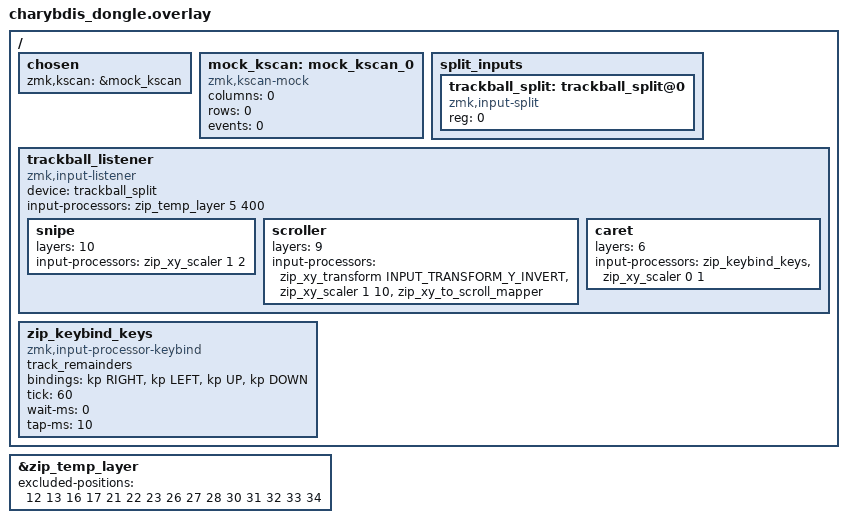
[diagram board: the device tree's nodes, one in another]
#include "../charybdis/charybdis-layout.dtsi"
#include <input/processors.dtsi>
#include <behaviors.dtsi>
#include <dt-bindings/zmk/keys.h>

/ {
    chosen {
        zmk,kscan = &mock_kscan;
    };

    mock_kscan: mock_kscan_0 {
        compatible = "zmk,kscan-mock";
        columns = <0>;
        rows = <0>;
        events = <0>;
    };

    split_inputs {
        #address-cells = <1>;
        #size-cells = <0>;
        trackball_split: trackball_split@0 {
            compatible = "zmk,input-split";
            reg = <0>;
        };
    };

    trackball_listener: trackball_listener {
        compatible = "zmk,input-listener";
        device = <&trackball_split>;
    };

    zip_keybind_keys: zip_keybind_keys {
        compatible = "zmk,input-processor-keybind";
        #input-processor-cells = <0>;
        track_remainders;
        bindings = <&kp RIGHT>,
                   <&kp LEFT>,
                   <&kp UP>,
                   <&kp DOWN>;
        tick = <60>;
        wait-ms = <0>;
        tap-ms = <10>;
    };
};

&zip_temp_layer {
    excluded-positions = <12 13 16 17 21 22 23 26 27 28 30 31 32 33 34>;
};

&trackball_listener {
    // automouse: при движении шара включается слой 5, выключается через 400 мс покоя
    input-processors = <&zip_temp_layer 5 400>;

    snipe {
        layers = <10>;
    // чем больше делитель (2), тем медленнее движется шар
        input-processors = <&zip_xy_scaler 1 2>;
    };

    scroller {
        layers = <9>;
        // чем больше делитель (10), тем медленнее работает скролл
        input-processors = <&zip_xy_transform INPUT_TRANSFORM_Y_INVERT
                            &zip_xy_scaler 1 10
                            &zip_xy_to_scroll_mapper>;
    };

        caret {
        layers = <6>;
        input-processors = <&zip_keybind_keys &zip_xy_scaler 0 1>;
    };
};
